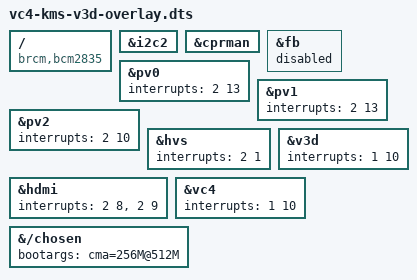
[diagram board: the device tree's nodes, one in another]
/*
 * vc4-kms-v3d-overlay.dts
 */

/dts-v1/;
/plugin/;

/ {
	compatible = "brcm,bcm2835", "brcm,bcm2708", "brcm,bcm2709";

	fragment@0 {
		target = <&i2c2>;
		__overlay__  {
			status = "okay";
		};
	};

	fragment@1 {
		target = <&cprman>;
		__overlay__  {
			status = "okay";
		};
	};

	fragment@2 {
		target = <&fb>;
		__overlay__  {
			status = "disabled";
		};
	};

	fragment@3 {
		target = <&pv0>;
		__overlay__  {
			interrupts = <2 13>; /* pwa0 */
			status = "okay";
		};
	};

	fragment@4 {
		target = <&pv1>;
		__overlay__  {
			interrupts = <2 13>; /* pwa0 */
			status = "okay";
		};
	};

	fragment@5 {
		target = <&pv2>;
		__overlay__  {
			interrupts = <2 10>; /* pixelvalve */
			status = "okay";
		};
	};

	fragment@6 {
		target = <&hvs>;
		__overlay__  {
			interrupts = <2 1>;
			status = "okay";
		};
	};

	fragment@7 {
		target = <&hdmi>;
		__overlay__  {
			interrupts = <2 8>, <2 9>;
			status = "okay";
		};
	};

	fragment@8 {
		target = <&v3d>;
		__overlay__  {
			interrupts = <1 10>;
			status = "okay";
		};
	};

	fragment@9 {
		target = <&vc4>;
		__overlay__  {
			interrupts = <1 10>;
			status = "okay";
		};
	};

	fragment@10 {
		target-path = "/chosen";
		__overlay__ {
			bootargs = "cma=256M@512M";
		};
	};
};
